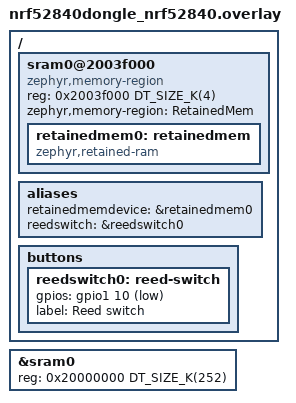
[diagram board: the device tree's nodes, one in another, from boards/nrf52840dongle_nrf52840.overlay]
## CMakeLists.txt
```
#
# Copyright (c) 2025 Jernej Pangerc
#
# SPDX-License-Identifier: Apache-2.0
#

cmake_minimum_required(VERSION 3.20.0)

find_package(Zephyr REQUIRED HINTS $ENV{ZEPHYR_BASE})
project(peripheral_ht)

FILE(GLOB app_sources src/*.c)
target_sources(app PRIVATE
  ${app_sources}
  )
```

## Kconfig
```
#
# Copyright (c) 2025 Jernej Pangerc
#
# SPDX-License-Identifier: Apache-2.0
#

menu "Bike trainer"

choice
	prompt "Select sensor type"
config USE_FTMS
	bool "Enable Fitnes Machine service"
	help
	  Use this if you are making a power meter - place the sensor
	  on a bike trainer. This service proveds power, speed and other
	  data to the smartphone or other client.

config USE_CSCS
	bool "Enable Cycling Speed and Cadence service"
	help
	  Use this if you are making a speed sensor - place the sensor
	  on a bike rim. This service doesn't calculate bike speed.
	  Bike speed is calculated by a smartphone or other client.

config USE_CPS
	bool "Enable Cycling Power service"
	help
	  Use this if you are making a power meter sensor.
	  This service doesn't calculate bike speed.
	  Bike speed is calculated by a smartphone or other client.
endchoice

config ROLLER_DIAMETER
	int "Roller diameter"
	depends on USE_FTMS
	help
	  Roller diameter in mm. Round to nearest integer. Used for indoor bike
	  to calculate speed and power. Roller is trainer's roller size.

config SWITCH_DEBOUNCE_TIME_MS
	int "Switch debounce time in ms"
	default 1
	help
	  Debounce time of a reed switch. If using quality switches, you can leave
	  default value. If using cheap switches, adjust the value.

config SHUTDOWN_TIME_S
	int "Shutdown time in s"
	default 60
	help
	  If there are no signals sensed on the sensor, the MCU will go to
	  system off after shutdown time.

endmenu

config BT_DIS_FW_REV_STR
	string
	depends on BT_DIS_FW_REV
	default "$(APPVERSION)"

source "Kconfig.zephyr"
```

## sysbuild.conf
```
#
# Copyright (c) 2025 Jernej Pangerc
#
# SPDX-License-Identifier: Apache-2.0
#

SB_CONFIG_BOOTLOADER_MCUBOOT=y
SB_CONFIG_BOOT_SIGNATURE_TYPE_RSA=y
```

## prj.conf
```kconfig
#
# Copyright (c) 2025 Jernej Pangerc
#
# SPDX-License-Identifier: Apache-2.0
#

CONFIG_BT=y
CONFIG_BT_SMP=y
CONFIG_BT_PERIPHERAL=y
CONFIG_BT_DEVICE_NAME="Nakapan trainer"
CONFIG_BT_DEVICE_APPEARANCE=1156

CONFIG_BT_DIS=y
CONFIG_BT_DIS_MANUF="Nakapan"
CONFIG_BT_DIS_MODEL="nrf52840 dongle"
CONFIG_BT_DIS_HW_REV=y
CONFIG_BT_DIS_HW_REV_STR="Prototype"
CONFIG_BT_DIS_FW_REV=y
CONFIG_BT_DIS_PNP=n

CONFIG_USE_FTMS=y
CONFIG_ROLLER_DIAMETER=54

CONFIG_NCS_SAMPLE_MCUMGR_BT_OTA_DFU=y
CONFIG_BOOTLOADER_MCUBOOT=y

CONFIG_POWEROFF=y
CONFIG_RETAINED_MEM=y
CONFIG_CRC=y
CONFIG_MINIMAL_LIBC=y

CONFIG_KERNEL_BIN_NAME="bike_trainer"
```

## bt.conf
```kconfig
#
# Copyright (c) 2025 Jernej Pangerc
#
# SPDX-License-Identifier: Apache-2.0
#

CONFIG_BT=y
CONFIG_BT_SMP=y
CONFIG_BT_PERIPHERAL=y
CONFIG_BT_DEVICE_NAME="Nakapan trainer"
CONFIG_BT_DEVICE_APPEARANCE=1156

CONFIG_USE_FTMS=y
CONFIG_ROLLER_DIAMETER=54

CONFIG_NCS_SAMPLE_MCUMGR_BT_OTA_DFU=y
CONFIG_KERNEL_BIN_NAME="bike_trainer"
```

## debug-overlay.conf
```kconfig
#
# Copyright (c) 2025 Jernej Pangerc
#
# SPDX-License-Identifier: Apache-2.0
#

CONFIG_LOG=y
CONFIG_GPIO=y
CONFIG_DEBUG_OPTIMIZATIONS=y

CONFIG_DEBUG_INFO=y
CONFIG_DEBUG_THREAD_INFO=y
CONFIG_INIT_STACKS=y
CONFIG_THREAD_ANALYZER=y
CONFIG_THREAD_ANALYZER_USE_LOG=y
CONFIG_THREAD_ANALYZER_AUTO=y
CONFIG_THREAD_ANALYZER_AUTO_INTERVAL=10


CONFIG_IDLE_STACK_SIZE=128
CONFIG_MAIN_STACK_SIZE=768
CONFIG_SYSTEM_WORKQUEUE_STACK_SIZE=1024
CONFIG_MPSL_WORK_STACK_SIZE=768
```

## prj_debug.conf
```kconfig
#
# Copyright (c) 2025 Jernej Pangerc
#
# SPDX-License-Identifier: Apache-2.0
#

CONFIG_LOG=y
CONFIG_GPIO=y
CONFIG_DEBUG_OPTIMIZATIONS=y

CONFIG_DEBUG_INFO=y
CONFIG_DEBUG_THREAD_INFO=y
CONFIG_INIT_STACKS=y
CONFIG_THREAD_ANALYZER=y
CONFIG_THREAD_ANALYZER_USE_LOG=y
CONFIG_THREAD_ANALYZER_AUTO=y
CONFIG_THREAD_ANALYZER_AUTO_INTERVAL=10

CONFIG_POWEROFF=y
CONFIG_RETAINED_MEM=y
CONFIG_CRC=y
CONFIG_MINIMAL_LIBC=y

CONFIG_IDLE_STACK_SIZE=128
CONFIG_MAIN_STACK_SIZE=768
CONFIG_SYSTEM_WORKQUEUE_STACK_SIZE=1024
CONFIG_MPSL_WORK_STACK_SIZE=768
```

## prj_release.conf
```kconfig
#
# Copyright (c) 2025 Jernej Pangerc
#
# SPDX-License-Identifier: Apache-2.0
#

CONFIG_LOG=n
CONFIG_GPIO=y

CONFIG_DEBUG=n
CONFIG_DEBUG_INFO=n
CONFIG_SERIAL=n
CONFIG_CONSOLE=n
CONFIG_UART_CONSOLE=n
CONFIG_PRINTK=n
CONFIG_NCS_BOOT_BANNER=n
CONFIG_BOOT_BANNER=n
CONFIG_USE_SEGGER_RTT=n
CONFIG_SIZE_OPTIMIZATIONS=y

CONFIG_POWEROFF=y
CONFIG_RETAINED_MEM=y
CONFIG_CRC=y
CONFIG_MINIMAL_LIBC=y

CONFIG_NRF_APPROTECT_LOCK=y
```

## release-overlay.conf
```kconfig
#
# Copyright (c) 2025 Jernej Pangerc
#
# SPDX-License-Identifier: Apache-2.0
#

CONFIG_LOG=n
CONFIG_GPIO=y

CONFIG_DEBUG=n
CONFIG_DEBUG_INFO=n
CONFIG_SERIAL=n
CONFIG_CONSOLE=n
CONFIG_UART_CONSOLE=n
CONFIG_PRINTK=n
CONFIG_NCS_BOOT_BANNER=n
CONFIG_BOOT_BANNER=n
CONFIG_USE_SEGGER_RTT=n
CONFIG_SIZE_OPTIMIZATIONS=y

CONFIG_NRF_APPROTECT_LOCK=y
```

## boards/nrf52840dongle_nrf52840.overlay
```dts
/ {
	sram0@2003f000 {
		compatible = "zephyr,memory-region", "mmio-sram";
		reg = <0x2003f000 DT_SIZE_K(4)>;
		zephyr,memory-region = "RetainedMem";
		status = "okay";

		retainedmem0: retainedmem {
			compatible = "zephyr,retained-ram";
			status = "okay";
		};
	};

	aliases {
		retainedmemdevice = &retainedmem0;
		reedswitch = &reedswitch0;
	};

	buttons {
		reedswitch0: reed-switch {
			gpios = <&gpio1 10 (GPIO_ACTIVE_LOW | GPIO_PULL_UP)>;
			label = "Reed switch";
		};
	};
};

&sram0 {
	/* Shrink SRAM size to avoid overlap with retained memory region */
	reg = <0x20000000 DT_SIZE_K(252)>;
};
```

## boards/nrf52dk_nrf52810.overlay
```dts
/ {
	sram0@20005000 {
		compatible = "zephyr,memory-region", "mmio-sram";
		reg = <0x20005000 DT_SIZE_K(4)>;
		zephyr,memory-region = "RetainedMem";
		status = "okay";

		retainedmem0: retainedmem {
			compatible = "zephyr,retained-ram";
			status = "okay";
		};
	};

	aliases {
		retainedmemdevice = &retainedmem0;
		reedswitch = &reedswitch0;
	};

	buttons {
		reedswitch0: reed-switch {
			gpios = <&gpio0 31 (GPIO_ACTIVE_LOW | GPIO_PULL_UP)>;
			label = "Reed switch";
		};
	};
};

&sram0 {
	/* Shrink SRAM size to avoid overlap with retained memory region */
	reg = <0x20000000 DT_SIZE_K(20)>;
};
```

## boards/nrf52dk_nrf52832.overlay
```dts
/ {
	sram0@2000F000 {
		compatible = "zephyr,memory-region", "mmio-sram";
		reg = <0x2000F000 DT_SIZE_K(4)>;
		zephyr,memory-region = "RetainedMem";
		status = "okay";

		retainedmem0: retainedmem {
			compatible = "zephyr,retained-ram";
			status = "okay";
		};
	};

	aliases {
		retainedmemdevice = &retainedmem0;
		reedswitch = &reedswitch0;
	};

	buttons {
		reedswitch0: reed-switch {
			gpios = <&gpio0 31 (GPIO_ACTIVE_LOW | GPIO_PULL_UP)>;
			label = "Reed switch";
		};
	};
};

&sram0 {
	/* Shrink SRAM size to avoid overlap with retained memory region */
	reg = <0x20000000 DT_SIZE_K(60)>;
};
```

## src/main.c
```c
/* main.c - Application main entry point */

/*
 * Copyright (c) 2025 Jernej Pangerc
 *
 * SPDX-License-Identifier: Apache-2.0
 */

#include <stddef.h>
#include <string.h>
#include <zephyr/drivers/gpio.h>
#include <zephyr/kernel.h>
#include <zephyr/logging/log.h>
#include <zephyr/sys/poweroff.h>
#include <zephyr/sys/printk.h>
#include <zephyr/types.h>

#if IS_ENABLED(CONFIG_USE_CSC)
#include "csc_service.h"
#else
#include "ftm_service.h"
#endif

/* Global variables section */
LOG_MODULE_REGISTER(main, LOG_LEVEL_DBG);

#if IS_ENABLED(CONFIG_DEBUG_INFO)
static const struct gpio_dt_spec user_led = GPIO_DT_SPEC_GET(DT_ALIAS(led2), gpios);
#endif
static const struct gpio_dt_spec user_switch = GPIO_DT_SPEC_GET(DT_ALIAS(reedswitch), gpios);

static struct gpio_callback switch_cb_data;

static uint64_t curr_time, prev_time;  // ms

uint16_t send_notify_flag;

void shutdown_cb(struct k_timer* timer);
K_TIMER_DEFINE(shutdown_timer, shutdown_cb, NULL);
/* End of global variables section */

/* Bluetooth section */
static const struct bt_data advertisement[] = {
    BT_DATA_BYTES(BT_DATA_FLAGS, (BT_LE_AD_GENERAL | BT_LE_AD_NO_BREDR)),
    BT_DATA_BYTES(BT_DATA_UUID16_ALL,
#if IS_ENABLED(CONFIG_USE_CSCS)
                  BT_UUID_16_ENCODE(BT_UUID_CSC_VAL)),
#elif IS_ENABLED(CONFIG_USE_FTMS)
                  BT_UUID_16_ENCODE(BT_UUID_FMS_VAL)),
    BT_DATA_BYTES(BT_DATA_SVC_DATA16, BT_UUID_16_ENCODE(BT_UUID_FMS_VAL), 0x01, 0x20, 0x00),  // indoor bike
#elif IS_ENABLED(CONFIG_USE_CPS)
                  BT_UUID_16_ENCODE(BT_UUID_CPS_VAL)),
#endif
};

static const struct bt_data scan_response[] = {
    BT_DATA(BT_DATA_NAME_COMPLETE, CONFIG_BT_DEVICE_NAME, sizeof(CONFIG_BT_DEVICE_NAME) - 1),
};

static void connected(struct bt_conn* conn, uint8_t err)
{
  if(err)
  {
    printk("Connection failed, err 0x%02x %s\n", err, bt_hci_err_to_str(err));
  }
  else
  {
    printk("Connected\n");
  }
}

static void disconnected(struct bt_conn* conn, uint8_t reason)
{
  printk("Disconnected, reason 0x%02x %s\n", reason, bt_hci_err_to_str(reason));
}

BT_CONN_CB_DEFINE(conn_callbacks) = {
    .connected = connected,
    .disconnected = disconnected,
};

static void bt_ready(void)
{
  int err;

  printk("Bluetooth initialized\n");

  err = bt_le_adv_start(BT_LE_ADV_CONN, advertisement, ARRAY_SIZE(advertisement), scan_response, ARRAY_SIZE(scan_response));
  if(err)
  {
    printk("Advertising failed to start (err %d)\n", err);
    return;
  }

  printk("Advertising successfully started\n");
}
/* End of bluetooth section */

/* GPIO section */
static void switch_cb_func(const struct device* port, struct gpio_callback* cb, gpio_port_pins_t pins)
{
  curr_time = k_uptime_get();
  if((curr_time - prev_time) > CONFIG_SWITCH_DEBOUNCE_TIME_MS)
  {
    k_timer_start(&shutdown_timer, K_SECONDS(CONFIG_SHUTDOWN_TIME_S), K_NO_WAIT);
    uint16_t time = (uint16_t)((curr_time - prev_time) & 0xFFFF);
    update_service_data(time);
#if IS_ENABLED(CONFIG_DEBUG_INFO)
    gpio_pin_toggle_dt(&user_led);
#endif
    prev_time = curr_time;
  }
}
/* End of GPIO section */

void shutdown_cb(struct k_timer* timer)
{
#if IS_ENABLED(CONFIG_DEBUG_INFO)
  gpio_pin_set_dt(&user_led, 0);
#endif
  retained_update();
  gpio_pin_interrupt_configure_dt(&user_switch, GPIO_INT_DISABLE);
  gpio_pin_interrupt_configure_dt(&user_switch, GPIO_INT_LEVEL_LOW);
  sys_poweroff();
  while(1);
}

int main(void)
{
  LOG_INF("Start of main.");
  int err;

#if IS_ENABLED(CONFIG_DEBUG_INFO)
  if(!gpio_is_ready_dt(&user_led))
  {
    return 0;
  }
  gpio_pin_configure_dt(&user_led, GPIO_OUTPUT_ACTIVE);
#endif
  if(!gpio_is_ready_dt(&user_switch))
  {
    return 0;
  }
  gpio_pin_configure_dt(&user_switch, GPIO_INPUT);
  gpio_pin_interrupt_configure_dt(&user_switch, GPIO_INT_EDGE_FALLING);

  gpio_init_callback(&switch_cb_data, switch_cb_func, BIT(user_switch.pin));
  gpio_add_callback_dt(&user_switch, &switch_cb_data);

  retained_validate();

  init_service_data();

  k_timer_start(&shutdown_timer, K_SECONDS(CONFIG_SHUTDOWN_TIME_S), K_NO_WAIT);

  err = bt_enable(NULL);
  if(err)
  {
    printk("Bluetooth init failed (err %d)\n", err);
    return 0;
  }

  bt_ready();

  while(1)
  {
    if(send_notify_flag)
    {
      notify_service();
    }
    k_sleep(K_SECONDS(1));
  }
  return 0;
}

/* Test thread for simulating spinning wheel. */
#if IS_ENABLED(CONFIG_DEBUG_INFO)
uint16_t millis = 50;
void sim_tread(void)
{
  while(1)
  {
    switch_cb_func(NULL, NULL, 0);
    k_sleep(K_MSEC(millis));
  }
}

#define SIM_THREAD_STACKSIZE 512
#define SIM_THREAD_PRIORITY 2
K_THREAD_DEFINE(sim_tread_id, SIM_THREAD_STACKSIZE, sim_tread, NULL, NULL, NULL, SIM_THREAD_PRIORITY, 0, 0);
#endif
```

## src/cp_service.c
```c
/* cp_service.c - Cycling Power Service module */

/*
 * Copyright (c) 2025 Jernej Pangerc
 *
 * SPDX-License-Identifier: Apache-2.0
 */

#include "cp_service.h"
#include <zephyr/drivers/retained_mem.h>
#include <zephyr/sys/byteorder.h>
#include <zephyr/sys/crc.h>

#if IS_ENABLED(CONFIG_USE_CPS)

#define RETAINED_CRC_OFFSET offsetof(cp_measurement_t, crc)
#define RETAINED_CHECKED_SIZE (RETAINED_CRC_OFFSET + sizeof(cpm_data.crc))

const static struct device* retained_mem_device = DEVICE_DT_GET(DT_ALIAS(retainedmemdevice));

cp_measurement_t cpm_data;

static void cpmc_ccc_cfg_changed(const struct bt_gatt_attr* attr, uint16_t value)
{
  send_notify_flag = value;
}

static ssize_t read_feature(struct bt_conn* conn,
                            const struct bt_gatt_attr* attr,
                            void* buf,
                            uint16_t len,
                            uint16_t offset)
{
  uint32_t value = CPF_CRANK_REV | CPF_DIST_SYS_NOT_FOR_DIST;  // CP Feature - Wheel Revolution Data Supported
  return bt_gatt_attr_read(conn, attr, buf, len, offset, &value, sizeof(value));
}

// Cycling Speed and Cadence Service Declaration
BT_GATT_SERVICE_DEFINE(csc_svc,
                       BT_GATT_PRIMARY_SERVICE(BT_UUID_CPS),
                       BT_GATT_CHARACTERISTIC(BT_UUID_GATT_CPS_CPF, BT_GATT_CHRC_READ,
                                              BT_GATT_PERM_READ, read_feature, NULL, NULL),
                       BT_GATT_CHARACTERISTIC(BT_UUID_GATT_CPS_CPM, BT_GATT_CHRC_NOTIFY,
                                              BT_GATT_PERM_NONE, NULL, NULL, NULL),
                       BT_GATT_CCC(cpmc_ccc_cfg_changed,
                                   BT_GATT_PERM_READ | BT_GATT_PERM_WRITE), );

void notify_service(void)
{
  uint16_t data_len = sizeof(cpm_data) - sizeof(cpm_data.crc);
  bt_gatt_notify(NULL, &csc_svc.attrs[3], &cpm_data, data_len);
}

void update_service_data(uint16_t time)
{
  cpm_data.crank_revolution++;
  cpm_data.last_crank_event_time += time;
}

void retained_validate(void)
{
  retained_mem_read(retained_mem_device, 0, (uint8_t*)&cpm_data, sizeof(cpm_data));

  /* The residue of a CRC is what you get from the CRC over the
   * message catenated with its CRC.  This is the post-final-xor
   * residue for CRC-32 (CRC-32/ISO-HDLC) which Zephyr calls
   * crc32_ieee.
   */
  const uint32_t residue = 0x2144df1c;
  uint32_t crc = crc32_ieee((const uint8_t*)&cpm_data, RETAINED_CHECKED_SIZE);
  bool valid = (crc == residue);

  /* If the CRC isn't valid, reset the retained data. */
  if(!valid)
  {
    memset(&cpm_data, 0, sizeof(cpm_data));
  }
}

void retained_update(void)
{
  uint32_t crc = crc32_ieee((const uint8_t*)&cpm_data, RETAINED_CRC_OFFSET);

  cpm_data.crc = sys_cpu_to_le32(crc);

  retained_mem_write(retained_mem_device, 0, (uint8_t*)&cpm_data, sizeof(cpm_data));
}

void init_service_data(void)
{
  cpm_data.flags = CPM_FLAG_CRANK_REV;  // Wheel Revolution Data Present
}
#endif  // IS_ENABLED(CONFIG_USE_CSC)
```

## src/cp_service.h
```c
/* cp_service.h - Cycling Power Service module */

/*
 * Copyright (c) 2025 Jernej Pangerc
 *
 * SPDX-License-Identifier: Apache-2.0
 */

#ifndef CSC_SERVICE_H
#define CSC_SERVICE_H

#include <zephyr/types.h>
#include <zephyr/bluetooth/bluetooth.h>
#include <zephyr/bluetooth/conn.h>
#include <zephyr/bluetooth/gatt.h>
#include <zephyr/bluetooth/hci.h>
#include <zephyr/bluetooth/services/bas.h>
#include <zephyr/bluetooth/uuid.h>

#define CPF_PEDAL_POWER (1 << 0)
#define CPF_ACC_TORQUE (1 << 1)
#define CPF_WHEEL_REV (1 << 2)
#define CPF_CRANK_REV (1 << 3)
#define CPF_EXTREME_MAGNITUDE (1 << 4)
#define CPF_EXTREME_ANGLE (1 << 5)
#define CPF_DEAD_SPOT_ANGLE (1 << 6)
#define CPF_ACC_ENERGY (1 << 7)
#define CPF_OFFSET_COMPENS_INDX (1 << 8)
#define CPF_OFFSET_COMPENS (1 << 9)
#define CPF_CPM_MASKING (1 << 10)
#define CPF_MULTI_SENSOR (1 << 11)
#define CPF_CRANK_LENGTH (1 << 12)
#define CPF_CHAIN_LENGTH (1 << 13)
#define CPF_CHAIN_WEIGTH (1 << 14)
#define CPF_SPAN_LENGTH (1 << 15)
#define CPF_SENSOR_MEASUREMENT (1 << 16)
#define CPF_INST_DIRECTION (1 << 17)
#define CPF_FACTORY_CALIB_DATE (1 << 18)
#define CPF_ENH_OFFSET (1 << 19)
#define CPF_DIST_SYS_UNSPEC (0 << 20)
#define CPF_DIST_SYS_NOT_FOR_DIST (1 << 20)
#define CPF_DIST_SYS_FOR_DIST (2 << 20)

#define CPM_FLAG_WHEEL_REV (1 << 4)
#define CPM_FLAG_CRANK_REV (1 << 5)

typedef struct __attribute__((packed))
{
  uint16_t flags;
  int16_t inst_power;
  //uint32_t wheel_revolution;
  //uint16_t last_wheel_event_time;
  uint16_t crank_revolution;
  uint16_t last_crank_event_time;
  /* CRC used to validate the retained data.  This must be
   * stored little-endian, and covers everything up to but not
   * including this field.
   */
  uint32_t crc;
} cp_measurement_t;

extern uint16_t send_notify_flag;

void notify_service(void);
void update_service_data(uint16_t time);
void init_service_data(void);
void retained_validate(void);
void retained_update(void);

#endif // CSC_SERVICE_H
```

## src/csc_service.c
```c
/* csc_service.c - Cycling Speed and Cadence Service module */

/*
 * Copyright (c) 2025 Jernej Pangerc
 *
 * SPDX-License-Identifier: Apache-2.0
 */

#include "csc_service.h"
#include <zephyr/sys/crc.h>
#include <zephyr/drivers/retained_mem.h>
#include <zephyr/sys/byteorder.h>

#if IS_ENABLED(CONFIG_USE_CSCS)

#define RETAINED_CRC_OFFSET offsetof(csc_measurement_t, crc)
#define RETAINED_CHECKED_SIZE (RETAINED_CRC_OFFSET + sizeof(cscm_data.crc))

const static struct device* retained_mem_device = DEVICE_DT_GET(DT_ALIAS(retainedmemdevice));

csc_measurement_t cscm_data;

static void cscmc_ccc_cfg_changed(const struct bt_gatt_attr *attr, uint16_t value)
{
    send_notify_flag = value;
}

static ssize_t read_feature(struct bt_conn *conn,
                            const struct bt_gatt_attr *attr,
                            void *buf,
                            uint16_t len,
                            uint16_t offset)
{
    uint16_t value = 1; // CSC Feature - Wheel Revolution Data Supported
    return bt_gatt_attr_read(conn, attr, buf, len, offset, &value, sizeof(value));
}

static ssize_t write_sc(struct bt_conn *conn,
                        const struct bt_gatt_attr *attr,
                        const void *buf,
                        uint16_t len, uint16_t offset, uint8_t flags)
{
    cscm_data.wheel_revolution = *((uint32_t *)buf);
    return len;
}

// Cycling Speed and Cadence Service Declaration
BT_GATT_SERVICE_DEFINE(csc_svc,
                       BT_GATT_PRIMARY_SERVICE(BT_UUID_CSC),
                       BT_GATT_CHARACTERISTIC(BT_UUID_CSC_MEASUREMENT, BT_GATT_CHRC_NOTIFY,
                                              BT_GATT_PERM_NONE, NULL, NULL, NULL),
                       BT_GATT_CCC(cscmc_ccc_cfg_changed,
                                   BT_GATT_PERM_READ | BT_GATT_PERM_WRITE),
                       BT_GATT_CHARACTERISTIC(BT_UUID_CSC_FEATURE, BT_GATT_CHRC_READ,
                                              BT_GATT_PERM_READ, read_feature, NULL, NULL),
                       BT_GATT_CHARACTERISTIC(BT_UUID_SC_CONTROL_POINT, BT_GATT_CHRC_WRITE,
                                              BT_GATT_PERM_WRITE, NULL, write_sc, NULL), );

void notify_service(void)
{
    bt_gatt_notify(NULL, &csc_svc.attrs[1], &cscm_data, sizeof(cscm_data));
}

void update_service_data(uint16_t time)
{
    cscm_data.wheel_revolution++;
    cscm_data.last_event_time += time;
}

void retained_validate(void)
{
  retained_mem_read(retained_mem_device, 0, (uint8_t*)&cscm_data, sizeof(cscm_data));

  /* The residue of a CRC is what you get from the CRC over the
   * message catenated with its CRC.  This is the post-final-xor
   * residue for CRC-32 (CRC-32/ISO-HDLC) which Zephyr calls
   * crc32_ieee.
   */
  const uint32_t residue = 0x2144df1c;
  uint32_t crc = crc32_ieee((const uint8_t*)&cscm_data, RETAINED_CHECKED_SIZE);
  bool valid = (crc == residue);

  /* If the CRC isn't valid, reset the retained data. */
  if(!valid)
  {
    memset(&cscm_data, 0, sizeof(cscm_data));
  }
}

void retained_update(void)
{
  uint32_t crc = crc32_ieee((const uint8_t*)&cscm_data, RETAINED_CRC_OFFSET);

  cscm_data.crc = sys_cpu_to_le32(crc);

  retained_mem_write(retained_mem_device, 0, (uint8_t*)&cscm_data, sizeof(cscm_data));
}

void init_service_data(void)
{
    cscm_data.flags = 1;  // Wheel Revolution Data Present
}
#endif //IS_ENABLED(CONFIG_USE_CSC)
```

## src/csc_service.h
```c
/* csc_service.h - Cycling Speed and Cadence Service module */

/*
 * Copyright (c) 2025 Jernej Pangerc
 *
 * SPDX-License-Identifier: Apache-2.0
 */

#ifndef CSC_SERVICE_H
#define CSC_SERVICE_H

#include <zephyr/types.h>
#include <zephyr/bluetooth/bluetooth.h>
#include <zephyr/bluetooth/conn.h>
#include <zephyr/bluetooth/gatt.h>
#include <zephyr/bluetooth/hci.h>
#include <zephyr/bluetooth/services/bas.h>
#include <zephyr/bluetooth/uuid.h>

typedef struct __attribute__((packed))
{
  uint8_t flags;
  uint32_t wheel_revolution;
  uint16_t last_event_time;
  /* CRC used to validate the retained data.  This must be
   * stored little-endian, and covers everything up to but not
   * including this field.
   */
  uint32_t crc;
} csc_measurement_t;

extern uint16_t send_notify_flag;

void notify_service(void);
void update_service_data(uint16_t time);
void init_service_data(void);
void retained_validate(void);
void retained_update(void);

#endif // CSC_SERVICE_H
```

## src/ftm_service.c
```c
/* ftm_service.c - Fitness Machine Service module */

/*
 * Copyright (c) 2025 Jernej Pangerc
 *
 * SPDX-License-Identifier: Apache-2.0
 */

#include "ftm_service.h"
#include "trainers/kinetic_road_machine.h"
#include <math.h>
#include <zephyr/drivers/retained_mem.h>
#include <zephyr/sys/byteorder.h>
#include <zephyr/sys/crc.h>

#if IS_ENABLED(CONFIG_USE_FTMS)
#define RETAINED_CRC_OFFSET offsetof(indoor_bike_data_t, crc)
#define RETAINED_CHECKED_SIZE (RETAINED_CRC_OFFSET + sizeof(indoor_bike_data.crc))

const static struct device* retained_mem_device = DEVICE_DT_GET(DT_ALIAS(retainedmemdevice));

indoor_bike_data_t indoor_bike_data;

float roller_rotations, inst_speed;
uint16_t floor, ceil, power;
static int64_t curr_time, prev_time;  // ms

static void ibdc_ccc_cfg_changed(const struct bt_gatt_attr* attr, uint16_t value)
{
  send_notify_flag = value;
}

static ssize_t read_fm_feature(struct bt_conn* conn,
                               const struct bt_gatt_attr* attr,
                               void* buf,
                               uint16_t len,
                               uint16_t offset)
{
  uint32_t fm_feature[2];
  fm_feature[0] = FMF_POWER_MEASURMENT; /* fitness machine features */
  fm_feature[1] = 0; /* target setting features */
  return bt_gatt_attr_read(conn, attr, buf, len, offset, &fm_feature, sizeof(fm_feature));
}

// Fitness Machine Service Declaration
BT_GATT_SERVICE_DEFINE(ftm_svc,
                       BT_GATT_PRIMARY_SERVICE(BT_UUID_FMS),
                       BT_GATT_CHARACTERISTIC(BT_UUID_GATT_FMF, BT_GATT_CHRC_READ,
                                              BT_GATT_PERM_READ, read_fm_feature, NULL, NULL),
                       BT_GATT_CHARACTERISTIC(BT_UUID_GATT_IBD, BT_GATT_CHRC_NOTIFY,
                                              BT_GATT_PERM_NONE, NULL, NULL, NULL),
                       BT_GATT_CCC(ibdc_ccc_cfg_changed,
                                   BT_GATT_PERM_READ | BT_GATT_PERM_WRITE), );

void notify_service(void)
{
  /* We calculate speed based on distance and time between notifications. */
  curr_time = k_uptime_get();
  int64_t delta = curr_time - prev_time;
  inst_speed = (float)(M_PI * CONFIG_ROLLER_DIAMETER) * roller_rotations / (float)delta * (float)3.6;  // km/h

  floor = (int16_t)(inst_speed / 10);  // floor to nearest 10 and get index
  ceil = floor + 1;  // ceil to nearest 10 and get index

  /* Use liner interpolation to calculate power between defined values. */
  /* y = (y0(x1-x) + y1(x-x0)) / (x1-x0) */
  /* y0 = powere_curve[floor] */
  /* y1 = powere_curve[ceil] */
  /* x0 = floor*10 (floor speed rounded to 10) */
  /* x1 = ceil*10 (ceil speed rounded to 10) */
  /* x = inst_speed */
  /* x1-x0 is alway 10, since we have steps of 10 km/h. */
  power = (uint16_t)((power_curve[floor] * (ceil * 10 - inst_speed) + power_curve[ceil] * (inst_speed - floor * 10)) / 10);

  indoor_bike_data.inst_power = power;

  uint16_t data_len = sizeof(indoor_bike_data) - sizeof(indoor_bike_data.crc);
  bt_gatt_notify(NULL, &ftm_svc.attrs[3], &indoor_bike_data, data_len);

  unsigned int key = irq_lock();
  roller_rotations = 0;
  irq_unlock(key);

  prev_time = curr_time;
}

/* This function is called from ISR, so it must be quick. */
void update_service_data(uint16_t time_ms)
{
  roller_rotations++;
}

void retained_validate(void)
{
  retained_mem_read(retained_mem_device, 0, (uint8_t*)&indoor_bike_data, sizeof(indoor_bike_data));

  /* The residue of a CRC is what you get from the CRC over the
   * message catenated with its CRC.  This is the post-final-xor
   * residue for CRC-32 (CRC-32/ISO-HDLC) which Zephyr calls
   * crc32_ieee.
   */
  const uint32_t residue = 0x2144df1c;
  uint32_t crc = crc32_ieee((const uint8_t*)&indoor_bike_data, RETAINED_CHECKED_SIZE);
  bool valid = (crc == residue);

  /* If the CRC isn't valid, reset the retained data. */
  if(!valid)
  {
    memset(&indoor_bike_data, 0, sizeof(indoor_bike_data));
  }
}

void retained_update(void)
{
  uint32_t crc = crc32_ieee((const uint8_t*)&indoor_bike_data, RETAINED_CRC_OFFSET);

  indoor_bike_data.crc = sys_cpu_to_le32(crc);

  retained_mem_write(retained_mem_device, 0, (uint8_t*)&indoor_bike_data, sizeof(indoor_bike_data));
}

void init_service_data(void)
{
  indoor_bike_data.flags = IBD_FLAG_INST_SPEED_NOT_PRESENT | IBD_FLAG_INST_POWER;
}
#endif  // IS_ENABLED(CONFIG_USE_FTMS)
```

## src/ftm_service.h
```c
/* ftm_service.h - Fitness Machine Service module */

/*
 * Copyright (c) 2025 Jernej Pangerc
 *
 * SPDX-License-Identifier: Apache-2.0
 */

#ifndef FTM_SERVICE_H
#define FTM_SERVICE_H

#include <zephyr/bluetooth/bluetooth.h>
#include <zephyr/bluetooth/conn.h>
#include <zephyr/bluetooth/gatt.h>
#include <zephyr/bluetooth/hci.h>
#include <zephyr/bluetooth/services/bas.h>
#include <zephyr/bluetooth/uuid.h>
#include <zephyr/types.h>

#define FMF_AVG_SPEED (1 << 0) /* Average Speed Supported */
#define FMF_CADENCE (1 << 1) /* Cadence Supported */
#define FMF_TOTAL_DIST (1 << 2) /* Total Distance Supported */
#define FMF_INCLINATION (1 << 3) /* Inclination Supported */
#define FMF_ELEVATION_GAIN (1 << 4) /* Elevation Gain Supported */
#define FMF_PACE (1 << 5) /* Pace Supported */
#define FMF_STEP_COUNT (1 << 6) /* Step Count Supported */
#define FMF_RESISTANCE_LEVEL (1 << 7) /* Resistance Level Supported */
#define FMF_STRIDE_COUNT (1 << 8) /* Stride Count Supported */
#define FMF_EXPENDED_ENERGY (1 << 9) /* Expended Energy Supported */
#define FMF_HEAR_RATE_MEASURMENT (1 << 10) /* Heart Rate Measurement Supported */
#define FMF_METABOLIC_EQV (1 << 11) /* Metabolic Equivalent Supported */
#define FMF_ELAPSED_TIME (1 << 12) /* Elapsed Time Supported */
#define FMF_REMAINING_TIME (1 << 13) /* Remaining Time Supported */
#define FMF_POWER_MEASURMENT (1 << 14) /* Power Measurement Supported */
#define FMF_FOCE_ON_BELT_POWER_OUT (1 << 15) /* Force on Belt and Power Output Supported */
#define FMF_USER_DATA_RET (1 << 16) /* User Data Retention Supported */

#define TSF_SPEED_TARGET (1 << 0) /* Speed Target Setting Supported */
#define TSF_INCLINATION_TARGET (1 << 1) /* Inclination Target Setting Supported */
#define TSF_RESISTANCE_TARGET (1 << 2) /* Resistance Target Setting Supported */
#define TSF_POWER_TARGET (1 << 3) /* Power Target Setting Supported */
#define TSF_HEART_RATE_TARGET (1 << 4) /* Heart Rate Target Setting Supported */
#define TSF_TARGET_EXPENDED_ENERGY (1 << 5) /* Targeted Expended Energy Configuration Supported */
#define TSF_TARGET_STEP_NUMBER (1 << 6) /* Targeted Step Number Configuration Supported */
#define TSF_STRIDE_STEP_NUMBER (1 << 7) /* Targeted Stride Number Configuration Supported */
#define TSF_TARGET_DISTANCE (1 << 8) /* Targeted Distance Configuration Supported */
#define TSF_TARGET_TRAIN_TIME (1 << 9) /* Targeted Training Time Configuration Supported */
#define TSF_TARGET_TIME_ZONES2 (1 << 10) /* Targeted Time in Two Heart Rate Zones Configuration Supported */
#define TSF_TARGET_TIME_ZONES3 (1 << 11) /* Targeted Time in Three Heart Rate Zones Configuration Supported */
#define TSF_TARGET_TIME_ZONES5 (1 << 12) /* Targeted Time in Five Heart Rate Zones Configuration Supported */
#define TSF_INDOOR_BIKE_SIM_PARAM (1 << 13) /* Indoor Bike Simulation Parameters Supported */
#define TSF_WHEEL_CIRCUMFERENCE (1 << 14) /* Wheel Circumference Configuration Supported */
#define TSF_SPINDOWN_CTRL (1 << 15) /* Spin Down Control Supported */
#define TSF_TARGET_CADENCE (1 << 16) /* Targeted Cadence Configuration Supported */

#define IBD_FLAG_INST_SPEED_PRESENT (0 << 0) /* Instantaneous Speed field present */
#define IBD_FLAG_INST_SPEED_NOT_PRESENT (1 << 0) /* Instantaneous Speed field not present */
#define IBD_FLAG_AVG_SPEED (1 << 1) /* Average Speed present */
#define IBD_FLAG_INST_CADENCE (1 << 2) /* Instantaneous Cadence present */
#define IBD_FLAG_AVG_CADENCE (1 << 3) /* Average Cadence present */
#define IBD_FLAG_TOTAL_DIST (1 << 4) /* Total Distance Present */
#define IBD_FLAG_RESISTANCE_LVL (1 << 5) /* Resistance Level Present */
#define IBD_FLAG_INST_POWER (1 << 6) /* Instantaneous Power Present */
#define IBD_FLAG_AVG_POWER (1 << 7) /* Average Power Present */
#define IBD_FLAG_EXPENDED_ENERGY (1 << 8) /* Expended Energy Present */
#define IBD_FLAG_HEART_RATE (1 << 9) /* Heart Rate Present */
#define IBD_FLAG_METABOLIC_EQV (1 << 10) /* Metabolic Equivalent Present */
#define IBD_FLAG_ELAPSED_TIME (1 << 11) /* Elapsed Time Present */
#define IBD_FLAG_REMAINING_TIME (1 << 12) /* Remaining Time Present */


typedef struct __attribute__((packed))
{
  uint16_t flags;
  //uint16_t inst_speed; /* km/h, resolution 0.01 km/h */
  //uint16_t avg_speed; /* km/h, resolution 0.01 km/h */
  //uint16_t inst_cadence; /* 1/min, resolution 0.5 min^-1*/
  //uint16_t avg_cadence; /* 1/min, resolution 0.5 min^-1*/
  //uint8_t total_dist[3]; /* m, resolution 1 m */
  //uint8_t resistance_lvl; /* no unit, resolution 0.1 */
  int16_t inst_power; /* W, resolution 1 W */
  //int16_t avg_power; /* W, resolution 1 W */
  //uint16_t total_energy; /* cal, resolution 1 cal */
  //uint16_t energy_per_hour; /* cal, resolution 1 cal */
  //uint8_t energy_per_minute; /* cal, resolution 1 cal */
  //uint8_t heart_rate; /* BPM, resolution 1 BMP */
  //uint8_t metabolic_eqv;
  //uint16_t elapsed_time; /* s, resolution 1 s */
  //uint16_t remaining_time; /* s, resolution 1 s */
  /* CRC used to validate the retained data.  This must be
   * stored little-endian, and covers everything up to but not
   * including this field.
   */
  uint32_t crc;
} indoor_bike_data_t;

extern uint16_t send_notify_flag;

void notify_service(void);
void update_service_data(uint16_t time);
void init_service_data(void);
void retained_validate(void);
void retained_update(void);

#endif  // CSC_SERVICE_H
```
